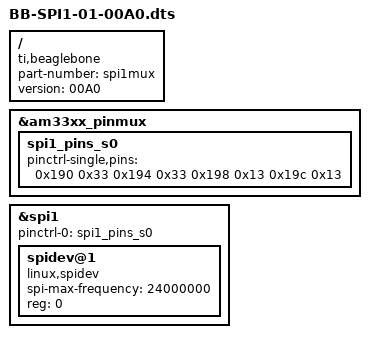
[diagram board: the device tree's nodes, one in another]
/* This Source Code Form is subject to the terms of the Mozilla Public
 * License, v. 2.0. If a copy of the MPL was not distributed with this
 * file, You can obtain one at http://mozilla.org/MPL/2.0/. */
/dts-v1/;
/plugin/;

/* SPI1 */
/* D1 output and D0 input */

/ {
    compatible = "ti,beaglebone", "ti,beaglebone-black";

    part-number = "spi1mux";
    version = "00A0";

    fragment@0 {
        target = <&am33xx_pinmux>;
        __overlay__ {
            spi1_pins_s0: spi1_pins_s0 {
                pinctrl-single,pins = <
                    0x190 0x33 /* P9_31 = spi1_sclk, INPUT_PULLUP | MODE3 */
                    0x194 0x33 /* P9_29 = spi1_d0, INPUT_PULLUP | MODE3 */
                    0x198 0x13 /* P9_30 = spi1_d1, OUTPUT_PULLUP | MODE3 */
                    0x19c 0x13 /* P9_28 = spi1_cs0, OUTPUT_PULLUP | MODE3 */
                >;
            };
        };
    };

    fragment@1 {
        target = <&spi1>;
        __overlay__ {
            #address-cells = <1>;
            #size-cells = <0>;

            status = "okay";
            pinctrl-names = "default";
            pinctrl-0 = <&spi1_pins_s0>;

            spidev@1 {
                spi-max-frequency = <24000000>;
                reg = <0>;
                compatible = "linux,spidev";
            };
        };
    };
};
